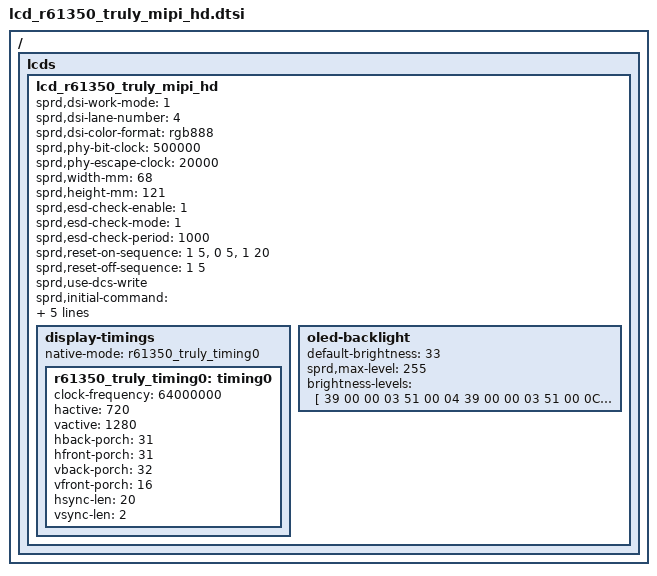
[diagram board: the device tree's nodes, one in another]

/*
 * R61350 Truly LCD config dtsi file for spreadtrum
 *
 * Copyright (C) 2018, Spreadtrum Communications Inc.
 *
 * SPDX-License-Identifier: (GPL-2.0 OR MIT)
 */

/ {
	fragment {
		target-path = "/";
		__overlay__ {
			lcds {
				lcd_r61350_truly_mipi_hd: lcd_r61350_truly_mipi_hd {

					sprd,dsi-work-mode = <1>; /* video burst mode*/
					sprd,dsi-lane-number = <4>;
					sprd,dsi-color-format = "rgb888";

					sprd,phy-bit-clock = <500000>;	/* kbps */
					sprd,phy-escape-clock = <20000>;/* kHz */

					sprd,width-mm = <68>;
					sprd,height-mm = <121>;

					sprd,esd-check-enable = <1>;
					sprd,esd-check-mode = <1>;
					sprd,esd-check-period = <1000>;
					/* sprd,esd-check-register = <0x0A>; */
					/* sprd,esd-check-value = <0x9C>; */

					sprd,reset-on-sequence = <1 5>, <0 5>, <1 20>;
					sprd,reset-off-sequence = <1 5>;

					sprd,use-dcs-write;
					sprd,initial-command = [
						//Host I/F Setting
						15 00 00 02 B0 00
						15 00 00 02 CC 04
						15 00 00 02 E3 01
						//DSI control
						39 00 00 03 B6 61 2C
						//display setting
						39 00 00 07 C0 23 B2 22 10 C2 7F
						//display h-timing setting
						39 00 00 17 C1 0B 6F 01 80 00 00 00 00 7F 03 08 08 08 08 08 08 08 08 08 08 08 08
						//stop recovery setting
						15 00 00 02 C3 75
						//display V-timing setting
						39 00 00 1D C5 06 06 40 43 00 00 03 01 80 07 00 00 00 00 00 00 00 0A 00 00 00 00 00 00 00 11 11 0E
						//panel drive setting
						39 00 00 03 C6 01 02
						//GOUT pin assignment
						39 00 00 3B C8 09 13 11 00 00 26 24 22 20 00 00 00 00 00 00 01 00 00 00 00 00 00 0A 13 11 00 00 27 25 23 21 00 00 00 00 00 00 02 00 00 00 00 00 00 89 00 00 00 01 00 00 00 02 00 00 00 03 00
						//Gamma setting
						39 00 00 27 CA 1B 29 32 41 4C 56 6C 7D 8B 97 4A 56 63 76 7F 8C 9B A8 BF 1B 29 32 41 4C 56 6C 7D 8B 97 4A 56 63 76 7F 8C 9B A8 BF
						//power setting for VCI1/2/3, DC2/3
						39 00 00 07 D0 01 4B 41 00 35 99
						//power setting for VCL,VCLLVL
						15 00 00 02 D1 03
						//power setting for external booster
						39 00 00 03 D2 8E 0B
						//register write control
						15 00 00 02 E5 02
						//VOCMDC setting
						39 00 00 03 D4 00 A0
						//VPLVL/VNLVL setting
						39 00 00 03 D5 24 24
						//TE ON
						15 00 00 02 35 00
						//CABC SETTING
						15 00 00 02 51 FF
						15 00 00 02 53 2C
						15 00 00 02 55 00
						//pause
						05 78 00 01 11
						05 32 00 01 29
						];

					sprd,sleep-in-command = [
						15 32 00 01 28
						15 96 00 01 10
						29 00 00 02 B0 00
						29 14 00 02 B1 01
						];

					sprd,sleep-out-command = [
						15 78 00 01 11
						15 32 00 01 29
						15 01 00 02 B0 00
						15 01 00 02 B1 01
						];

					display-timings {
						native-mode = <&r61350_truly_timing0>;

						r61350_truly_timing0: timing0 {
							clock-frequency = <64000000>;
							hactive = <720>;
							vactive = <1280>;
							hback-porch = <31>;
							hfront-porch = <31>;
							vback-porch = <32>;
							vfront-porch = <16>;
							hsync-len = <20>;
							vsync-len = <2>;
						};
					};
										oled-backlight {			
						default-brightness = <33>;	
						sprd,max-level = <255>;
						brightness-levels =[				
							39 00 00 03 51 00 04	
							39 00 00 03 51 00 0C
							39 00 00 03 51 01 04
							39 00 00 03 51 01 0C
							39 00 00 03 51 02 05
							39 00 00 03 51 02 0D
							39 00 00 03 51 03 05
							39 00 00 03 51 03 0D
							39 00 00 03 51 04 05
							39 00 00 03 51 04 0D
							39 00 00 03 51 05 05
							39 00 00 03 51 05 0D
							39 00 00 03 51 06 05
							39 00 00 03 51 06 0D
							39 00 00 03 51 07 05
							39 00 00 03 51 07 0D
							39 00 00 03 51 08 05
							39 00 00 03 51 08 0D
							39 00 00 03 51 09 05
							39 00 00 03 51 09 0D
							39 00 00 03 51 0A 05
							39 00 00 03 51 0A 0D
							39 00 00 03 51 0B 05
							39 00 00 03 51 0B 0D
							39 00 00 03 51 0C 05
							39 00 00 03 51 0C 0D
							39 00 00 03 51 0D 05
							39 00 00 03 51 0D 0D
							39 00 00 03 51 0E 05
							39 00 00 03 51 0E 0E
							39 00 00 03 51 0F 06
							39 00 00 03 51 0F 0E
							39 00 00 03 51 10 06
							39 00 00 03 51 10 0E
							39 00 00 03 51 11 06
							39 00 00 03 51 11 0E
							39 00 00 03 51 12 06
							39 00 00 03 51 12 0E
							39 00 00 03 51 13 06
							39 00 00 03 51 13 0E
							39 00 00 03 51 14 06
							39 00 00 03 51 14 0E
							39 00 00 03 51 15 06
							39 00 00 03 51 15 0E
							39 00 00 03 51 16 06
							39 00 00 03 51 16 0E
							39 00 00 03 51 17 06
							39 00 00 03 51 17 0E
							39 00 00 03 51 18 06
							39 00 00 03 51 18 0E
							39 00 00 03 51 19 06
							39 00 00 03 51 19 0E
							39 00 00 03 51 1A 06
							39 00 00 03 51 1A 0E
							39 00 00 03 51 1B 07
							39 00 00 03 51 1B 0F
							39 00 00 03 51 1C 07
							39 00 00 03 51 1C 0F
							39 00 00 03 51 1D 07
							39 00 00 03 51 1D 0F
							39 00 00 03 51 1E 07
							39 00 00 03 51 1E 0F
							39 00 00 03 51 1F 07
							39 00 00 03 51 1F 0F
							39 00 00 03 51 20 07
							39 00 00 03 51 20 0F
							39 00 00 03 51 21 07
							39 00 00 03 51 21 0F
							39 00 00 03 51 22 07
							39 00 00 03 51 22 0F
							39 00 00 03 51 23 07
							39 00 00 03 51 23 0F
							39 00 00 03 51 24 07
							39 00 00 03 51 24 0F
							39 00 00 03 51 25 07
							39 00 00 03 51 25 0F
							39 00 00 03 51 26 07
							39 00 00 03 51 26 0F
							39 00 00 03 51 27 07
							39 00 00 03 51 28 00
							39 00 00 03 51 28 08
							39 00 00 03 51 29 00
							39 00 00 03 51 29 08
							39 00 00 03 51 2A 00
							39 00 00 03 51 2A 08
							39 00 00 03 51 2B 00
							39 00 00 03 51 2B 08
							39 00 00 03 51 2C 00
							39 00 00 03 51 2C 08
							39 00 00 03 51 2D 00
							39 00 00 03 51 2D 08
							39 00 00 03 51 2E 00
							39 00 00 03 51 2E 08
							39 00 00 03 51 2F 00
							39 00 00 03 51 2F 08
							39 00 00 03 51 30 00
							39 00 00 03 51 30 08
							39 00 00 03 51 31 00
							39 00 00 03 51 31 08
							39 00 00 03 51 32 00
							39 00 00 03 51 32 08
							39 00 00 03 51 33 00
							39 00 00 03 51 33 08
							39 00 00 03 51 34 00
							39 00 00 03 51 34 09
							39 00 00 03 51 35 01
							39 00 00 03 51 35 09
							39 00 00 03 51 36 01
							39 00 00 03 51 36 09
							39 00 00 03 51 37 01
							39 00 00 03 51 37 09
							39 00 00 03 51 38 01
							39 00 00 03 51 38 09
							39 00 00 03 51 39 01
							39 00 00 03 51 39 09
							39 00 00 03 51 3A 01
							39 00 00 03 51 3A 09
							39 00 00 03 51 3B 01
							39 00 00 03 51 3B 09
							39 00 00 03 51 3C 01
							39 00 00 03 51 3C 09
							39 00 00 03 51 3D 01
							39 00 00 03 51 3D 09
							39 00 00 03 51 3E 01
							39 00 00 03 51 3E 09
							39 00 00 03 51 3F 01
							39 00 00 03 51 3F 09
							39 00 00 03 51 40 01
							39 00 00 03 51 40 09
							39 00 00 03 51 41 02
							39 00 00 03 51 41 0A
							39 00 00 03 51 42 02
							39 00 00 03 51 42 0A
							39 00 00 03 51 43 02
							39 00 00 03 51 43 0A
							39 00 00 03 51 44 02
							39 00 00 03 51 44 0A
							39 00 00 03 51 45 02
							39 00 00 03 51 45 0A
							39 00 00 03 51 46 02
							39 00 00 03 51 46 0A
							39 00 00 03 51 47 02
							39 00 00 03 51 47 0A
							39 00 00 03 51 48 02
							39 00 00 03 51 48 0A
							39 00 00 03 51 49 02
							39 00 00 03 51 49 0A
							39 00 00 03 51 4A 02
							39 00 00 03 51 4A 0A
							39 00 00 03 51 4B 02
							39 00 00 03 51 4B 0A
							39 00 00 03 51 4C 02
							39 00 00 03 51 4C 0A
							39 00 00 03 51 4D 02
							39 00 00 03 51 4D 0B
							39 00 00 03 51 4E 03
							39 00 00 03 51 4E 0B
							39 00 00 03 51 4F 03
							39 00 00 03 51 4F 0B
							39 00 00 03 51 50 03
							39 00 00 03 51 50 0B
							39 00 00 03 51 51 03
							39 00 00 03 51 51 0B
							39 00 00 03 51 52 03
							39 00 00 03 51 52 0B
							39 00 00 03 51 53 03
							39 00 00 03 51 53 0B
							39 00 00 03 51 54 03
							39 00 00 03 51 54 0B
							39 00 00 03 51 55 03
							39 00 00 03 51 55 0B
							39 00 00 03 51 56 03
							39 00 00 03 51 56 0B
							39 00 00 03 51 57 03
							39 00 00 03 51 57 0B
							39 00 00 03 51 58 03
							39 00 00 03 51 58 0B
							39 00 00 03 51 59 03
							39 00 00 03 51 59 0B
							39 00 00 03 51 5A 04
							39 00 00 03 51 5A 0C
							39 00 00 03 51 5B 04
							39 00 00 03 51 5B 0C
							39 00 00 03 51 5C 04
							39 00 00 03 51 5C 0C
							39 00 00 03 51 5D 04
							39 00 00 03 51 5D 0C
							39 00 00 03 51 5E 04
							39 00 00 03 51 5E 0C
							39 00 00 03 51 5F 04
							39 00 00 03 51 5F 0C
							39 00 00 03 51 60 04
							39 00 00 03 51 60 0C
							39 00 00 03 51 61 04
							39 00 00 03 51 61 0C
							39 00 00 03 51 62 04
							39 00 00 03 51 62 0C
							39 00 00 03 51 63 04
							39 00 00 03 51 63 0C
							39 00 00 03 51 64 04
							39 00 00 03 51 64 0C
							39 00 00 03 51 65 04
							39 00 00 03 51 65 0C
							39 00 00 03 51 66 04
							39 00 00 03 51 66 0D
							39 00 00 03 51 67 05
							39 00 00 03 51 67 0D
							39 00 00 03 51 68 05
							39 00 00 03 51 68 0D
							39 00 00 03 51 69 05
							39 00 00 03 51 69 0D
							39 00 00 03 51 6A 05
							39 00 00 03 51 6A 0D
							39 00 00 03 51 6B 05
							39 00 00 03 51 6B 0D
							39 00 00 03 51 6C 05
							39 00 00 03 51 6C 0D
							39 00 00 03 51 6D 05
							39 00 00 03 51 6D 0D
							39 00 00 03 51 6E 05
							39 00 00 03 51 6E 0D
							39 00 00 03 51 6F 05
							39 00 00 03 51 6F 0D
							39 00 00 03 51 70 05
							39 00 00 03 51 70 0D
							39 00 00 03 51 71 05
							39 00 00 03 51 71 0D
							39 00 00 03 51 72 05
							39 00 00 03 51 72 0D
							39 00 00 03 51 73 06
							39 00 00 03 51 73 0E
							39 00 00 03 51 74 06
							39 00 00 03 51 74 0E
							39 00 00 03 51 75 06
							39 00 00 03 51 75 0E
							39 00 00 03 51 76 06
							39 00 00 03 51 76 0E
							39 00 00 03 51 77 06
							39 00 00 03 51 77 0E
							39 00 00 03 51 78 06
							39 00 00 03 51 78 0E
							39 00 00 03 51 79 06
							39 00 00 03 51 79 0E
							39 00 00 03 51 7A 06
							39 00 00 03 51 7A 0E
							39 00 00 03 51 7B 06
							39 00 00 03 51 7B 0E
							39 00 00 03 51 7C 06
							39 00 00 03 51 7C 0E
							39 00 00 03 51 7D 06
							39 00 00 03 51 7D 0E
							39 00 00 03 51 7E 06
							39 00 00 03 51 7E 0E
							39 00 00 03 51 7F 06
							39 00 00 03 51 7F 0F
						];
					};
				};
			};
		};
	};
};
